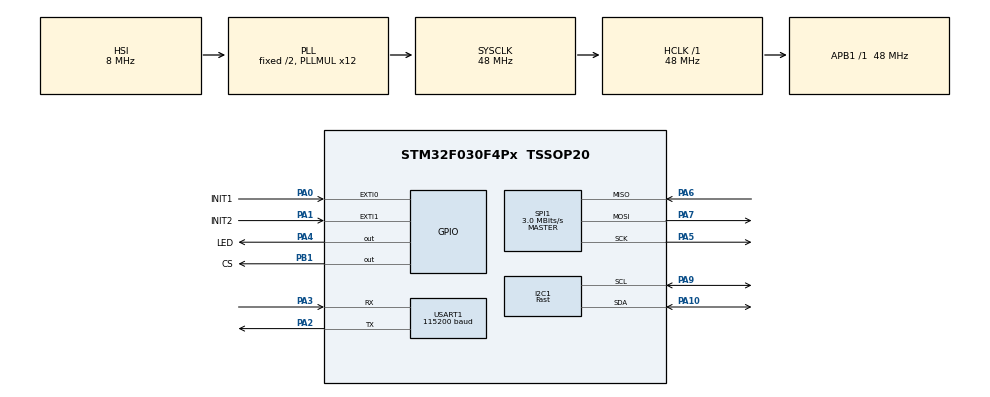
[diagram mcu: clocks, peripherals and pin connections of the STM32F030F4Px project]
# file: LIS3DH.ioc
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Dma.I2C1_RX.0.Direction=DMA_PERIPH_TO_MEMORY
Dma.I2C1_RX.0.Instance=DMA1_Channel3
Dma.I2C1_RX.0.MemDataAlignment=DMA_MDATAALIGN_BYTE
Dma.I2C1_RX.0.MemInc=DMA_MINC_ENABLE
Dma.I2C1_RX.0.Mode=DMA_NORMAL
Dma.I2C1_RX.0.PeriphDataAlignment=DMA_PDATAALIGN_BYTE
Dma.I2C1_RX.0.PeriphInc=DMA_PINC_DISABLE
Dma.I2C1_RX.0.Priority=DMA_PRIORITY_HIGH
Dma.Request0=I2C1_RX
Dma.Request1=USART1_RX
Dma.Request2=SPI1_RX
Dma.SPI1_RX.2.Direction=DMA_PERIPH_TO_MEMORY
Dma.SPI1_RX.2.Instance=DMA1_Channel2
Dma.SPI1_RX.2.MemDataAlignment=DMA_MDATAALIGN_BYTE
Dma.SPI1_RX.2.MemInc=DMA_MINC_ENABLE
Dma.SPI1_RX.2.Mode=DMA_NORMAL
Dma.SPI1_RX.2.PeriphDataAlignment=DMA_PDATAALIGN_BYTE
Dma.SPI1_RX.2.PeriphInc=DMA_PINC_DISABLE
Dma.SPI1_RX.2.Priority=DMA_PRIORITY_MEDIUM
Dma.USART1_RX.1.Direction=DMA_PERIPH_TO_MEMORY
Dma.USART1_RX.1.Instance=DMA1_Channel5
Dma.USART1_RX.1.MemDataAlignment=DMA_MDATAALIGN_BYTE
Dma.USART1_RX.1.MemInc=DMA_MINC_ENABLE
Dma.USART1_RX.1.Mode=DMA_NORMAL
Dma.USART1_RX.1.PeriphDataAlignment=DMA_PDATAALIGN_BYTE
Dma.USART1_RX.1.PeriphInc=DMA_PINC_DISABLE
Dma.USART1_RX.1.Priority=DMA_PRIORITY_LOW
I2C1.I2C_Speed_Mode=I2C_Fast
I2C1.Speed=400
I2C1.Timing=0x0000020B
IWDG.Prescaler=IWDG_PRESCALER_256
Mcu.Family=STM32F0
Mcu.Name=STM32F030F4Px
Mcu.Package=TSSOP20
NVIC.DMA1_Channel2_3_IRQn=true\:0\:0\:false\:false\:true\:false\:true
NVIC.DMA1_Channel4_5_IRQn=true\:0\:0\:false\:false\:true\:false\:true
NVIC.EXTI0_1_IRQn=true\:0\:0\:false\:false\:true\:true\:true
NVIC.USART1_IRQn=true\:0\:0\:false\:false\:true\:true\:true
PA0.GPIO_Label=INIT1
PA0.Signal=GPXTI0
PA1.GPIO_Label=INIT2
PA1.Signal=GPXTI1
PA10.Mode=I2C
PA10.Signal=I2C1_SDA
PA13.Mode=Serial_Wire
PA13.Signal=SYS_SWDIO
PA14.Mode=Serial_Wire
PA14.Signal=SYS_SWCLK
PA2.Mode=Asynchronous
PA2.Signal=USART1_TX
PA3.Mode=Asynchronous
PA3.Signal=USART1_RX
PA4.GPIO_Label=LED
PA4.Signal=GPIO_Output
PA5.Mode=Full_Duplex_Master
PA5.Signal=SPI1_SCK
PA6.Mode=Full_Duplex_Master
PA6.Signal=SPI1_MISO
PA7.Mode=Full_Duplex_Master
PA7.Signal=SPI1_MOSI
PA9.Mode=I2C
PA9.Signal=I2C1_SCL
PB1.GPIO_Label=CS
PB1.PinState=GPIO_PIN_SET
PB1.Signal=GPIO_Output
ProjectManager.HeapSize=0x200
ProjectManager.StackSize=0x400
ProjectManager.TargetToolchain=MDK-ARM V5
RCC.AHBFreq_Value=48000000
RCC.APB1Freq_Value=48000000
RCC.APB1TimFreq_Value=48000000
RCC.HCLKFreq_Value=48000000
RCC.PLLMUL=RCC_PLL_MUL12
RCC.SYSCLKFreq_VALUE=48000000
RCC.SYSCLKSource=RCC_SYSCLKSOURCE_PLLCLK
SPI1.BaudRatePrescaler=SPI_BAUDRATEPRESCALER_16
SPI1.CLKPolarity=SPI_POLARITY_LOW
SPI1.CalculateBaudRate=3.0 MBits/s
SPI1.DataSize=SPI_DATASIZE_8BIT
SPI1.Direction=SPI_DIRECTION_2LINES
SPI1.Mode=SPI_MODE_MASTER
SPI1.VirtualType=VM_MASTER
USART1.BaudRate=115200
USART1.VirtualMode-Asynchronous=VM_ASYNC
VP_CRC_VS_CRC.Mode=CRC_Activate
VP_IWDG_VS_IWDG.Mode=IWDG_Activate
VP_RTC_VS_RTC_Activate.Mode=RTC_Enabled
board=custom

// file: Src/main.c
/* USER CODE BEGIN Header */
/**
  ******************************************************************************
  * @file           : main.c
  * @brief          : Main program body
  ******************************************************************************
  * @attention
  *
  * <h2><center>&copy; Copyright (c) 2019 STMicroelectronics.
  * All rights reserved.</center></h2>
  *
  * This software component is licensed by ST under BSD 3-Clause license,
  * the "License"; You may not use this file except in compliance with the
  * License. You may obtain a copy of the License at:
  *                        opensource.org/licenses/BSD-3-Clause
  *
  ******************************************************************************
  */
/* USER CODE END Header */

#include "main.h"
#include "defines.h"
#include "lis3dh_driver.h"

CRC_HandleTypeDef hcrc;

I2C_HandleTypeDef hi2c1;
DMA_HandleTypeDef hdma_i2c1_rx;

IWDG_HandleTypeDef hiwdg;

RTC_HandleTypeDef hrtc;

SPI_HandleTypeDef hspi1;
DMA_HandleTypeDef hdma_spi1_rx;

UART_HandleTypeDef huart1;
DMA_HandleTypeDef hdma_usart1_rx;

/* USER CODE BEGIN PV */
int fputc(int ch,FILE *f)
{
    uint8_t temp[1]={ch};
    HAL_UART_Transmit(&huart1,temp,1,2);        //UartHandle
		return ch;
}

/* USER CODE END PV */

void SystemClock_Config(void);
static void MX_GPIO_Init(void);
static void MX_DMA_Init(void);
static void MX_I2C1_Init(void);
static void MX_USART1_UART_Init(void);
static void MX_SPI1_Init(void);
static void MX_CRC_Init(void);
static void MX_IWDG_Init(void);
static void MX_RTC_Init(void);

/* USER CODE BEGIN 0 */
/* USER CODE BEGIN 0 */
extern AxesRaw_t leitura;
extern AxesRaw_t leitura_inicial;
extern float Angulo;
/* USER CODE END 0 */

int main(void)
{

  /* MCU Configuration--------------------------------------------------------*/

  /* Reset of all peripherals, Initializes the Flash interface and the Systick. */
  HAL_Init();

  /* Configure the system clock */
  SystemClock_Config();

  /* USER CODE BEGIN SysInit */
	//uint8_t TST=0x55;
	//uint8_t ID=0x00;
	uint8_t ADCVAL[6];
	uint8_t buff=0x00;
	uint8_t lan[32];
	i8_t buf=0x00;

  /* USER CODE END SysInit */
  MX_IWDG_Init();
	HAL_IWDG_Refresh(&hiwdg);
  /* Initialize all configured peripherals */
  MX_GPIO_Init();
  MX_DMA_Init();
  MX_I2C1_Init();
  MX_USART1_UART_Init();
  MX_SPI1_Init();
  MX_CRC_Init();
  MX_RTC_Init();
	LIS3DH_Init();
	if(LIS3DH_WHO_NAME == WhoAmI) {
		printf("\n");
		printf("ctrl_reg:%X %X %X %X %X %X %X \n",ctrl_reg[0],ctrl_reg[1],ctrl_reg[2],ctrl_reg[3],ctrl_reg[4],ctrl_reg[5],ctrl_reg[6]);
		printf("int1_reg :%X %X %X\n",Int1_cfg,Int1_ths,Int1_dur);
		printf("\n");
	}
	LIS3DH_SetClickCFG(LIS3DH_XD_ENABLE|LIS3DH_YD_ENABLE);
  /* USER CODE BEGIN 2 */

	//HAL_I2C_Mem_Write(&hi2c1, 0X30,0X22,1, &TST, 1, 1000);
  /* Infinite loop */
  /* USER CODE BEGIN WHILE */
  while (1)
  {
		HAL_IWDG_Refresh(&hiwdg);
		//HAL_I2C_Mem_Read(&hi2c1, LIS3DH_I2C_ADDRESS,LIS3DH_WHO_AM_I,1, &buff, 1, 1000);
		//HAL_I2C_Mem_Read(&hi2c1, 0X30,0X22,1, &TST, 1, 1000);
//		LIS3DH_GetWHO_AM_I(&buff);
//		printf("WHO_AM_I :%X\n",buff);
//		LIS3DH_GetStatusAUX(&buff);
//		printf("StatusAUX :%X\n",buff);
    /* USER CODE END WHILE */

		if(DataReady)
		{
			DataReady = 0;
			//Angulo = GetAngle(leitura.AXIS_X,leitura.AXIS_Y,leitura.AXIS_Z,0,0,GRAVIDADE);
			//printf("LIS3DH_GetAngle :%f\n",Angulo);
			printf("DataReady :%X %X %X\n",leitura.AXIS_X,leitura.AXIS_Y,leitura.AXIS_Z);

		}
		/* USER CODE END WHILE */
		//LIS3DH_GetTempRaw(&buf);
		//if (LIS3DH_GetInt1Src(&buff))	printf("LIS3DH_GetInt1Src :%X\n",buff);
    /* USER CODE END WHILE */

//		LIS3DH_GetTempRaw(ADCVAL);
//
//		LIS3DH_GetAccAxesRaw(&leitura);
//		printf("AccAxesRaw :%X %X %X\n",leitura.AXIS_X,leitura.AXIS_Y,leitura.AXIS_Z);

		//LIS3DH_GetFifoSourceReg(&buff);
//		LIS3DH_GetFifoSourceFSS(&buff);
//		printf("FifoSourceFSS :%X\n",buff);
		//if(buff>1)HAL_I2C_Mem_Read(&hi2c1, 0XB0,0X2B,1,lan, buff, 1000);
		//while(buff--) printf("Fifo %X:%X ",buff,lan[buff]);
//		LIS3DH_GetClickResponse(&buff);
//		printf("GetClickResponse :%X\n",buff);
//		Angulo = GetAngle(leitura.AXIS_X,leitura.AXIS_Y,leitura.AXIS_Z,0,0,GRAVIDADE);
//		printf("LIS3DH_GetAngle :%f\n",Angulo);
//		LIS3DH_GetAccAxesRaw(&leitura);
//		printf("AccAxesRaw :%X %X %X\n",leitura.AXIS_X,leitura.AXIS_Y,leitura.AXIS_Z);
		//LIS3DH_SetADCAux(State_t state);
    /* USER CODE END WHILE */
		HAL_Delay(400);
		HAL_GPIO_TogglePin(LED_GPIO_Port,LED_Pin);
		buff=0x00;
		buf=0x00;
		printf("\n");
  }
}

void SystemClock_Config(void)
{
  RCC_OscInitTypeDef RCC_OscInitStruct = {0};
  RCC_ClkInitTypeDef RCC_ClkInitStruct = {0};
  RCC_PeriphCLKInitTypeDef PeriphClkInit = {0};

  /** Initializes the CPU, AHB and APB busses clocks
  */
  RCC_OscInitStruct.OscillatorType = RCC_OSCILLATORTYPE_HSI|RCC_OSCILLATORTYPE_LSI;
  RCC_OscInitStruct.HSIState = RCC_HSI_ON;
  RCC_OscInitStruct.HSICalibrationValue = RCC_HSICALIBRATION_DEFAULT;
  RCC_OscInitStruct.LSIState = RCC_LSI_ON;
  RCC_OscInitStruct.PLL.PLLState = RCC_PLL_ON;
  RCC_OscInitStruct.PLL.PLLSource = RCC_PLLSOURCE_HSI;
  RCC_OscInitStruct.PLL.PLLMUL = RCC_PLL_MUL12;
  RCC_OscInitStruct.PLL.PREDIV = RCC_PREDIV_DIV1;
  if (HAL_RCC_OscConfig(&RCC_OscInitStruct) != HAL_OK)
  {
    Error_Handler();
  }
  /** Initializes the CPU, AHB and APB busses clocks
  */
  RCC_ClkInitStruct.ClockType = RCC_CLOCKTYPE_HCLK|RCC_CLOCKTYPE_SYSCLK
                              |RCC_CLOCKTYPE_PCLK1;
  RCC_ClkInitStruct.SYSCLKSource = RCC_SYSCLKSOURCE_PLLCLK;
  RCC_ClkInitStruct.AHBCLKDivider = RCC_SYSCLK_DIV1;
  RCC_ClkInitStruct.APB1CLKDivider = RCC_HCLK_DIV1;

  if (HAL_RCC_ClockConfig(&RCC_ClkInitStruct, FLASH_LATENCY_1) != HAL_OK)
  {
    Error_Handler();
  }
  PeriphClkInit.PeriphClockSelection = RCC_PERIPHCLK_USART1|RCC_PERIPHCLK_I2C1
                              |RCC_PERIPHCLK_RTC;
  PeriphClkInit.Usart1ClockSelection = RCC_USART1CLKSOURCE_PCLK1;
  PeriphClkInit.I2c1ClockSelection = RCC_I2C1CLKSOURCE_HSI;
  PeriphClkInit.RTCClockSelection = RCC_RTCCLKSOURCE_LSI;
  if (HAL_RCCEx_PeriphCLKConfig(&PeriphClkInit) != HAL_OK)
  {
    Error_Handler();
  }
}

static void MX_CRC_Init(void)
{

  hcrc.Instance = CRC;
  hcrc.Init.DefaultPolynomialUse = DEFAULT_POLYNOMIAL_ENABLE;
  hcrc.Init.DefaultInitValueUse = DEFAULT_INIT_VALUE_ENABLE;
  hcrc.Init.InputDataInversionMode = CRC_INPUTDATA_INVERSION_NONE;
  hcrc.Init.OutputDataInversionMode = CRC_OUTPUTDATA_INVERSION_DISABLE;
  hcrc.InputDataFormat = CRC_INPUTDATA_FORMAT_BYTES;
  if (HAL_CRC_Init(&hcrc) != HAL_OK)
  {
    Error_Handler();
  }

}

static void MX_I2C1_Init(void)
{

  hi2c1.Instance = I2C1;
  hi2c1.Init.Timing = 0x0000020B;
  hi2c1.Init.OwnAddress1 = 0;
  hi2c1.Init.AddressingMode = I2C_ADDRESSINGMODE_7BIT;
  hi2c1.Init.DualAddressMode = I2C_DUALADDRESS_DISABLE;
  hi2c1.Init.OwnAddress2 = 0;
  hi2c1.Init.OwnAddress2Masks = I2C_OA2_NOMASK;
  hi2c1.Init.GeneralCallMode = I2C_GENERALCALL_DISABLE;
  hi2c1.Init.NoStretchMode = I2C_NOSTRETCH_DISABLE;
  if (HAL_I2C_Init(&hi2c1) != HAL_OK)
  {
    Error_Handler();
  }
  /** Configure Analogue filter
  */
  if (HAL_I2CEx_ConfigAnalogFilter(&hi2c1, I2C_ANALOGFILTER_ENABLE) != HAL_OK)
  {
    Error_Handler();
  }
  /** Configure Digital filter
  */
  if (HAL_I2CEx_ConfigDigitalFilter(&hi2c1, 0) != HAL_OK)
  {
    Error_Handler();
  }

}

static void MX_IWDG_Init(void)
{

  hiwdg.Instance = IWDG;
  hiwdg.Init.Prescaler = IWDG_PRESCALER_64;
  hiwdg.Init.Window = 4095;
  hiwdg.Init.Reload = 4095;
  if (HAL_IWDG_Init(&hiwdg) != HAL_OK)
  {
    Error_Handler();
  }

}

static void MX_RTC_Init(void)
{

  /** Initialize RTC Only
  */
  hrtc.Instance = RTC;
  hrtc.Init.HourFormat = RTC_HOURFORMAT_24;
  hrtc.Init.AsynchPrediv = 127;
  hrtc.Init.SynchPrediv = 255;
  hrtc.Init.OutPut = RTC_OUTPUT_DISABLE;
  hrtc.Init.OutPutPolarity = RTC_OUTPUT_POLARITY_HIGH;
  hrtc.Init.OutPutType = RTC_OUTPUT_TYPE_OPENDRAIN;
  if (HAL_RTC_Init(&hrtc) != HAL_OK)
  {
    Error_Handler();
  }

}

static void MX_SPI1_Init(void)
{

  /* SPI1 parameter configuration*/
  hspi1.Instance = SPI1;
  hspi1.Init.Mode = SPI_MODE_MASTER;
  hspi1.Init.Direction = SPI_DIRECTION_2LINES;
  hspi1.Init.DataSize = SPI_DATASIZE_8BIT;
  hspi1.Init.CLKPolarity = SPI_POLARITY_LOW;
  hspi1.Init.CLKPhase = SPI_PHASE_1EDGE;
  hspi1.Init.NSS = SPI_NSS_SOFT;
  hspi1.Init.BaudRatePrescaler = SPI_BAUDRATEPRESCALER_16;
  hspi1.Init.FirstBit = SPI_FIRSTBIT_MSB;
  hspi1.Init.TIMode = SPI_TIMODE_DISABLE;
  hspi1.Init.CRCCalculation = SPI_CRCCALCULATION_DISABLE;
  hspi1.Init.CRCPolynomial = 7;
  hspi1.Init.CRCLength = SPI_CRC_LENGTH_DATASIZE;
  hspi1.Init.NSSPMode = SPI_NSS_PULSE_ENABLE;
  if (HAL_SPI_Init(&hspi1) != HAL_OK)
  {
    Error_Handler();
  }

}

static void MX_USART1_UART_Init(void)
{

  huart1.Instance = USART1;
  huart1.Init.BaudRate = 115200;
  huart1.Init.WordLength = UART_WORDLENGTH_8B;
  huart1.Init.StopBits = UART_STOPBITS_1;
  huart1.Init.Parity = UART_PARITY_NONE;
  huart1.Init.Mode = UART_MODE_TX_RX;
  huart1.Init.HwFlowCtl = UART_HWCONTROL_NONE;
  huart1.Init.OverSampling = UART_OVERSAMPLING_16;
  huart1.Init.OneBitSampling = UART_ONE_BIT_SAMPLE_DISABLE;
  huart1.AdvancedInit.AdvFeatureInit = UART_ADVFEATURE_NO_INIT;
  if (HAL_UART_Init(&huart1) != HAL_OK)
  {
    Error_Handler();
  }

}

static void MX_DMA_Init(void)
{
  /* DMA controller clock enable */
  __HAL_RCC_DMA1_CLK_ENABLE();

  /* DMA interrupt init */
  /* DMA1_Channel2_3_IRQn interrupt configuration */
  HAL_NVIC_SetPriority(DMA1_Channel2_3_IRQn, 0, 0);
  HAL_NVIC_EnableIRQ(DMA1_Channel2_3_IRQn);
  /* DMA1_Channel4_5_IRQn interrupt configuration */
  HAL_NVIC_SetPriority(DMA1_Channel4_5_IRQn, 0, 0);
  HAL_NVIC_EnableIRQ(DMA1_Channel4_5_IRQn);

}

static void MX_GPIO_Init(void)
{
  GPIO_InitTypeDef GPIO_InitStruct = {0};

  /* GPIO Ports Clock Enable */
  __HAL_RCC_GPIOA_CLK_ENABLE();
  __HAL_RCC_GPIOB_CLK_ENABLE();

  /*Configure GPIO pin Output Level */
  HAL_GPIO_WritePin(LED_GPIO_Port, LED_Pin, GPIO_PIN_RESET);

  /*Configure GPIO pin Output Level */
  HAL_GPIO_WritePin(CS_GPIO_Port, CS_Pin, GPIO_PIN_SET);

  /*Configure GPIO pins : INIT1_Pin INIT2_Pin */
  GPIO_InitStruct.Pin = INIT1_Pin|INIT2_Pin;
  GPIO_InitStruct.Mode = GPIO_MODE_IT_RISING;
  GPIO_InitStruct.Pull = GPIO_NOPULL;
  HAL_GPIO_Init(GPIOA, &GPIO_InitStruct);

  /*Configure GPIO pin : LED_Pin */
  GPIO_InitStruct.Pin = LED_Pin;
  GPIO_InitStruct.Mode = GPIO_MODE_OUTPUT_PP;
  GPIO_InitStruct.Pull = GPIO_NOPULL;
  GPIO_InitStruct.Speed = GPIO_SPEED_FREQ_LOW;
  HAL_GPIO_Init(LED_GPIO_Port, &GPIO_InitStruct);

  /*Configure GPIO pin : CS_Pin */
  GPIO_InitStruct.Pin = CS_Pin;
  GPIO_InitStruct.Mode = GPIO_MODE_OUTPUT_PP;
  GPIO_InitStruct.Pull = GPIO_NOPULL;
  GPIO_InitStruct.Speed = GPIO_SPEED_FREQ_LOW;
  HAL_GPIO_Init(CS_GPIO_Port, &GPIO_InitStruct);

  /* EXTI interrupt init*/
  HAL_NVIC_SetPriority(EXTI0_1_IRQn, 0, 0);
  HAL_NVIC_EnableIRQ(EXTI0_1_IRQn);

}

void Error_Handler(void)
{
}

/************************ (C) COPYRIGHT STMicroelectronics *****END OF FILE****/
